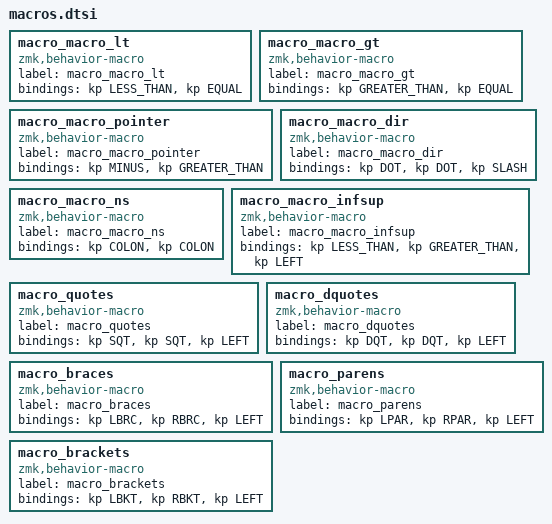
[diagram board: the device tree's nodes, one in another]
macro_macro_lt: macro_macro_lt{
compatible = "zmk,behavior-macro";
label = "macro_macro_lt";
#binding-cells = <0>;
bindings = <&kp LESS_THAN>, <&kp EQUAL>;
};
macro_macro_gt: macro_macro_gt{
compatible = "zmk,behavior-macro";
label = "macro_macro_gt";
#binding-cells = <0>;
bindings = <&kp GREATER_THAN>, <&kp EQUAL>;
};
macro_macro_pointer: macro_macro_pointer{
compatible = "zmk,behavior-macro";
label = "macro_macro_pointer";
#binding-cells = <0>;
bindings = <&kp MINUS>, <&kp GREATER_THAN>;
};
macro_macro_dir: macro_macro_dir{
compatible = "zmk,behavior-macro";
label = "macro_macro_dir";
#binding-cells = <0>;
bindings = <&kp DOT>, <&kp DOT>, <&kp SLASH>;
};
macro_macro_ns: macro_macro_ns{
compatible = "zmk,behavior-macro";
label = "macro_macro_ns";
#binding-cells = <0>;
bindings = <&kp COLON>, <&kp COLON>;
};
macro_macro_infsup: macro_macro_infsup{
compatible = "zmk,behavior-macro";
label = "macro_macro_infsup";
#binding-cells = <0>;
bindings = <&kp LESS_THAN>, <&kp GREATER_THAN>, <&kp LEFT>;
};
macro_quotes: macro_quotes{
compatible = "zmk,behavior-macro";
label = "macro_quotes";
#binding-cells = <0>;
bindings = <&kp SQT>, <&kp SQT>, <&kp LEFT>;
};
macro_dquotes: macro_dquotes{
compatible = "zmk,behavior-macro";
label = "macro_dquotes";
#binding-cells = <0>;
bindings = <&kp DQT>, <&kp DQT>, <&kp LEFT>;
};
macro_braces: macro_braces{
compatible = "zmk,behavior-macro";
label = "macro_braces";
#binding-cells = <0>;
bindings = <&kp LBRC>, <&kp RBRC>, <&kp LEFT>;
};
macro_parens: macro_parens{
compatible = "zmk,behavior-macro";
label = "macro_parens";
#binding-cells = <0>;
bindings = <&kp LPAR>, <&kp RPAR>, <&kp LEFT>;
};
macro_brackets: macro_brackets{
compatible = "zmk,behavior-macro";
label = "macro_brackets";
#binding-cells = <0>;
bindings = <&kp LBKT>, <&kp RBKT>, <&kp LEFT>;
};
